VERSION ""

NS_ :

BS_:

BU_: Bms

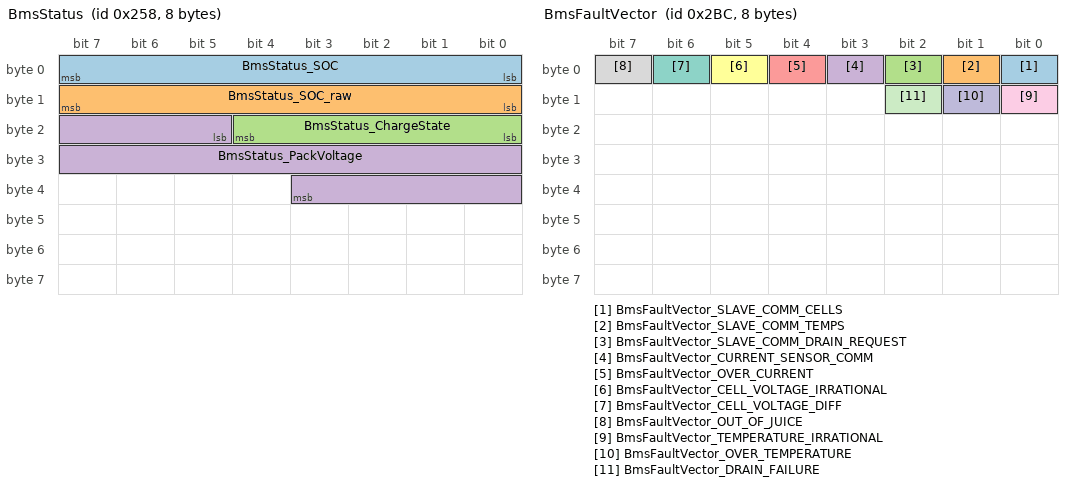
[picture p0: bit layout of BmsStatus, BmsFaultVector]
BO_ 600 BmsStatus: 8  Bms
 SG_ BmsStatus_SOC: 0|8@1+ (1,0) [0|100] "%" Vector__XXX
 SG_ BmsStatus_SOC_raw: 8|8@1+ (1,0) [0|100] "%" Vector__XXX
 SG_ BmsStatus_ChargeState: 16|5@1+ (1,0) [0|4] "" Vector__XXX
 SG_ BmsStatus_PackVoltage: 21|15@1+ (0.1,0) [0|400] "V" Vector__XXX

BO_ 700 BmsFaultVector: 8 Bms
 SG_ BmsFaultVector_SLAVE_COMM_CELLS : 0|1@1+ (1,0) [0|1] "" Vector__XXX
 SG_ BmsFaultVector_SLAVE_COMM_TEMPS : 1|1@1+ (1,0) [0|1] "" Vector__XXX
 SG_ BmsFaultVector_SLAVE_COMM_DRAIN_REQUEST : 2|1@1+ (1,0) [0|1] "" Vector__XXX
 SG_ BmsFaultVector_CURRENT_SENSOR_COMM : 3|1@1+ (1,0) [0|1] "" Vector__XXX
 SG_ BmsFaultVector_OVER_CURRENT : 4|1@1+ (1,0) [0|1] "" Vector__XXX
 SG_ BmsFaultVector_CELL_VOLTAGE_IRRATIONAL : 5|1@1+ (1,0) [0|1] "" Vector__XXX
 SG_ BmsFaultVector_CELL_VOLTAGE_DIFF : 6|1@1+ (1,0) [0|1] "" Vector__XXX
 SG_ BmsFaultVector_OUT_OF_JUICE : 7|1@1+ (1,0) [0|1] "" Vector__XXX
 SG_ BmsFaultVector_TEMPERATURE_IRRATIONAL: 8|1@1+ (1,0) [0|1] "" Vector__XXX
 SG_ BmsFaultVector_OVER_TEMPERATURE: 9|1@1+ (1,0) [0|1] "" Vector__XXX
 SG_ BmsFaultVector_DRAIN_FAILURE: 10|1@1+ (1,0) [0|1] "" Vector__XXX

BO_ 701 BmsFaultAlert: 8 Bms
 SG_ BmsFaultAlert_code M : 0|6@1+ (1,0) [0|63] "" Vector__XXX
 SG_ BmsFaultAlert_cell_comm_slave_board_num m0: 6|8@1+ (1,0) [0|255] "" Vector__XXX
 SG_ BmsFaultAlert_temp_comm_slave_board_num m1: 6|8@1+ (1,0) [0|255] "" Vector__XXX
 SG_ BmsFaultAlert_drain_comm_slave_board_num m2: 6|8@1+ (1,0) [0|255] "" Vector__XXX
 SG_ BmsFaultAlert_adc_error_code m3: 6|8@1+ (1,0) [0|255] "" Vector__XXX
 SG_ BmsFaultAlert_current m4: 6|32@1+ (0.001,0) [0|2000] "A" Vector__XXX
 SG_ BmsFaultAlert_irrational_voltage m5: 6|9@1+ (0.01,0) [0|5.12] "V" Vector__XXX
 SG_ BmsFaultAlert_voltage_diff m6: 6|9@1+ (0.01,0) [0|5.12] "V" Vector__XXX
 SG_ BmsFaultAlert_lowest_cell_voltage m7: 6|9@1+ (0.01,0) [0|5.12] "V" Vector__XXX
 SG_ BmsFaultAlert_irrational_temperature m8: 6|16@1+ (0.01,0) [-327.68|327.67] "V" Vector__XXX
 SG_ BmsFaultAlert_over_temperature m9: 6|16@1+ (0.01,0) [-327.68|327.67] "V" Vector__XXX
 SG_ BmsFaultAlert_failed_drain_cell m10: 6|8@1+ (1,0) [0|255] "" Vector__XXX

BO_ 702 BmsVoltages: 8 Bms
 SG_ BmsVoltages_mux M : 0|8@1+ (1,0) [0|255] "" Vector__XXX
 SG_ BmsVoltages_Cell0 m0 : 8|9@1+ (0.01,0) [0|5.12] "V" Vector__XXX
 SG_ BmsVoltages_Cell1 m0 : 17|9@1+ (0.01,0) [0|5.12] "V" Vector__XXX
 SG_ BmsVoltages_Cell2 m0 : 26|9@1+ (0.01,0) [0|5.12] "V" Vector__XXX
 SG_ BmsVoltages_Cell3 m0 : 35|9@1+ (0.01,0) [0|5.12] "V" Vector__XXX
 SG_ BmsVoltages_Cell4 m0 : 44|9@1+ (0.01,0) [0|5.12] "V" Vector__XXX
 SG_ BmsVoltages_Cell5 m0 : 53|9@1+ (0.01,0) [0|5.12] "V" Vector__XXX
 SG_ BmsVoltages_Cell6 m1 : 8|9@1+ (0.01,0) [0|5.12] "V" Vector__XXX
 SG_ BmsVoltages_Cell7 m1 : 17|9@1+ (0.01,0) [0|5.12] "V" Vector__XXX
 SG_ BmsVoltages_Cell8 m1 : 26|9@1+ (0.01,0) [0|5.12] "V" Vector__XXX
 SG_ BmsVoltages_Cell9 m1 : 35|9@1+ (0.01,0) [0|5.12] "V" Vector__XXX
 SG_ BmsVoltages_Cell10 m1 : 44|9@1+ (0.01,0) [0|5.12] "V" Vector__XXX
 SG_ BmsVoltages_Cell11 m1 : 53|9@1+ (0.01,0) [0|5.12] "V" Vector__XXX
 SG_ BmsVoltages_Cell12 m2 : 8|9@1+ (0.01,0) [0|5.12] "V" Vector__XXX
 SG_ BmsVoltages_Cell13 m2 : 17|9@1+ (0.01,0) [0|5.12] "V" Vector__XXX
 SG_ BmsVoltages_Cell14 m2 : 26|9@1+ (0.01,0) [0|5.12] "V" Vector__XXX
 SG_ BmsVoltages_Cell15 m2 : 35|9@1+ (0.01,0) [0|5.12] "V" Vector__XXX
 SG_ BmsVoltages_Cell16 m2 : 44|9@1+ (0.01,0) [0|5.12] "V" Vector__XXX
 SG_ BmsVoltages_Cell17 m2 : 53|9@1+ (0.01,0) [0|5.12] "V" Vector__XXX
 SG_ BmsVoltages_Cell18 m3 : 8|9@1+ (0.01,0) [0|5.12] "V" Vector__XXX
 SG_ BmsVoltages_Cell19 m3 : 17|9@1+ (0.01,0) [0|5.12] "V" Vector__XXX
 SG_ BmsVoltages_Cell20 m3 : 26|9@1+ (0.01,0) [0|5.12] "V" Vector__XXX
 SG_ BmsVoltages_Cell21 m3 : 35|9@1+ (0.01,0) [0|5.12] "V" Vector__XXX
 SG_ BmsVoltages_Cell22 m3 : 44|9@1+ (0.01,0) [0|5.12] "V" Vector__XXX
 SG_ BmsVoltages_Cell23 m3 : 53|9@1+ (0.01,0) [0|5.12] "V" Vector__XXX
 SG_ BmsVoltages_Cell24 m4 : 8|9@1+ (0.01,0) [0|5.12] "V" Vector__XXX
 SG_ BmsVoltages_Cell25 m4: 17|9@1+ (0.01,0) [0|5.12] "V" Vector__XXX
 SG_ BmsVoltages_Cell26 m4: 26|9@1+ (0.01,0) [0|5.12] "V" Vector__XXX
 SG_ BmsVoltages_Cell27 m4: 35|9@1+ (0.01,0) [0|5.12] "V" Vector__XXX
 SG_ BmsVoltages_Cell28 m4: 44|9@1+ (0.01,0) [0|5.12] "V" Vector__XXX
 SG_ BmsVoltages_Cell29 m4: 53|9@1+ (0.01,0) [0|5.12] "V" Vector__XXX
 SG_ BmsVoltages_Cell30 m5: 8|9@1+ (0.01,0) [0|5.12] "V" Vector__XXX
 SG_ BmsVoltages_Cell31 m5: 17|9@1+ (0.01,0) [0|5.12] "V" Vector__XXX
 SG_ BmsVoltages_Cell32 m5: 26|9@1+ (0.01,0) [0|5.12] "V" Vector__XXX
 SG_ BmsVoltages_Cell33 m5: 35|9@1+ (0.01,0) [0|5.12] "V" Vector__XXX
 SG_ BmsVoltages_Cell34 m5: 44|9@1+ (0.01,0) [0|5.12] "V" Vector__XXX
 SG_ BmsVoltages_Cell35 m5: 53|9@1+ (0.01,0) [0|5.12] "V" Vector__XXX
 SG_ BmsVoltages_Cell36 m6: 8|9@1+ (0.01,0) [0|5.12] "V" Vector__XXX
 SG_ BmsVoltages_Cell37 m6: 17|9@1+ (0.01,0) [0|5.12] "V" Vector__XXX
 SG_ BmsVoltages_Cell38 m6: 26|9@1+ (0.01,0) [0|5.12] "V" Vector__XXX
 SG_ BmsVoltages_Cell39 m6: 35|9@1+ (0.01,0) [0|5.12] "V" Vector__XXX
 SG_ BmsVoltages_Cell40 m6: 44|9@1+ (0.01,0) [0|5.12] "V" Vector__XXX
 SG_ BmsVoltages_Cell41 m6: 53|9@1+ (0.01,0) [0|5.12] "V" Vector__XXX
 SG_ BmsVoltages_Cell42 m7: 8|9@1+ (0.01,0) [0|5.12] "V" Vector__XXX
 SG_ BmsVoltages_Cell43 m7: 17|9@1+ (0.01,0) [0|5.12] "V" Vector__XXX
 SG_ BmsVoltages_Cell44 m7: 26|9@1+ (0.01,0) [0|5.12] "V" Vector__XXX
 SG_ BmsVoltages_Cell45 m7: 35|9@1+ (0.01,0) [0|5.12] "V" Vector__XXX
 SG_ BmsVoltages_Cell46 m7: 44|9@1+ (0.01,0) [0|5.12] "V" Vector__XXX
 SG_ BmsVoltages_Cell47 m7: 53|9@1+ (0.01,0) [0|5.12] "V" Vector__XXX
 SG_ BmsVoltages_Cell48 m8: 8|9@1+ (0.01,0) [0|5.12] "V" Vector__XXX
 SG_ BmsVoltages_Cell49 m8: 17|9@1+ (0.01,0) [0|5.12] "V" Vector__XXX
 SG_ BmsVoltages_Cell50 m8: 26|9@1+ (0.01,0) [0|5.12] "V" Vector__XXX
 SG_ BmsVoltages_Cell51 m8: 35|9@1+ (0.01,0) [0|5.12] "V" Vector__XXX
 SG_ BmsVoltages_Cell52 m8: 44|9@1+ (0.01,0) [0|5.12] "V" Vector__XXX
 SG_ BmsVoltages_Cell53 m8: 53|9@1+ (0.01,0) [0|5.12] "V" Vector__XXX
 SG_ BmsVoltages_Cell54 m9: 8|9@1+ (0.01,0) [0|5.12] "V" Vector__XXX
 SG_ BmsVoltages_Cell55 m9: 17|9@1+ (0.01,0) [0|5.12] "V" Vector__XXX
 SG_ BmsVoltages_Cell56 m9: 26|9@1+ (0.01,0) [0|5.12] "V" Vector__XXX
 SG_ BmsVoltages_Cell57 m9: 35|9@1+ (0.01,0) [0|5.12] "V" Vector__XXX
 SG_ BmsVoltages_Cell58 m9: 44|9@1+ (0.01,0) [0|5.12] "V" Vector__XXX
 SG_ BmsVoltages_Cell59 m9: 53|9@1+ (0.01,0) [0|5.12] "V" Vector__XXX
 SG_ BmsVoltages_Cell60 m10: 8|9@1+ (0.01,0) [0|5.12] "V" Vector__XXX
 SG_ BmsVoltages_Cell61 m10: 17|9@1+ (0.01,0) [0|5.12] "V" Vector__XXX
 SG_ BmsVoltages_Cell62 m10: 26|9@1+ (0.01,0) [0|5.12] "V" Vector__XXX
 SG_ BmsVoltages_Cell63 m10: 35|9@1+ (0.01,0) [0|5.12] "V" Vector__XXX
 SG_ BmsVoltages_Cell64 m10: 44|9@1+ (0.01,0) [0|5.12] "V" Vector__XXX
 SG_ BmsVoltages_Cell65 m10: 53|9@1+ (0.01,0) [0|5.12] "V" Vector__XXX
 SG_ BmsVoltages_Cell66 m11: 8|9@1+ (0.01,0) [0|5.12] "V" Vector__XXX
 SG_ BmsVoltages_Cell67 m11: 17|9@1+ (0.01,0) [0|5.12] "V" Vector__XXX
 SG_ BmsVoltages_Cell68 m11: 26|9@1+ (0.01,0) [0|5.12] "V" Vector__XXX
 SG_ BmsVoltages_Cell69 m11: 35|9@1+ (0.01,0) [0|5.12] "V" Vector__XXX
 SG_ BmsVoltages_Cell70 m11: 44|9@1+ (0.01,0) [0|5.12] "V" Vector__XXX
 SG_ BmsVoltages_Cell71 m11: 53|9@1+ (0.01,0) [0|5.12] "V" Vector__XXX
 SG_ BmsVoltages_Cell72 m12: 8|9@1+ (0.01,0) [0|5.12] "V" Vector__XXX
 SG_ BmsVoltages_Cell73 m12: 17|9@1+ (0.01,0) [0|5.12] "V" Vector__XXX
 SG_ BmsVoltages_Cell74 m12: 26|9@1+ (0.01,0) [0|5.12] "V" Vector__XXX
 SG_ BmsVoltages_Cell75 m12: 35|9@1+ (0.01,0) [0|5.12] "V" Vector__XXX
 SG_ BmsVoltages_Cell76 m12: 44|9@1+ (0.01,0) [0|5.12] "V" Vector__XXX
 SG_ BmsVoltages_Cell77 m12: 53|9@1+ (0.01,0) [0|5.12] "V" Vector__XXX
 SG_ BmsVoltages_Cell78 m13: 8|9@1+ (0.01,0) [0|5.12] "V" Vector__XXX
 SG_ BmsVoltages_Cell79 m13: 17|9@1+ (0.01,0) [0|5.12] "V" Vector__XXX
 SG_ BmsVoltages_Cell80 m13: 26|9@1+ (0.01,0) [0|5.12] "V" Vector__XXX
 SG_ BmsVoltages_Cell81 m13: 35|9@1+ (0.01,0) [0|5.12] "V" Vector__XXX
 SG_ BmsVoltages_Cell82 m13: 44|9@1+ (0.01,0) [0|5.12] "V" Vector__XXX
 SG_ BmsVoltages_Cell83 m13: 53|9@1+ (0.01,0) [0|5.12] "V" Vector__XXX
 SG_ BmsVoltages_Cell84 m14: 8|9@1+ (0.01,0) [0|5.12] "V" Vector__XXX
 SG_ BmsVoltages_Cell85 m14: 17|9@1+ (0.01,0) [0|5.12] "V" Vector__XXX
 SG_ BmsVoltages_Cell86 m14: 26|9@1+ (0.01,0) [0|5.12] "V" Vector__XXX
 SG_ BmsVoltages_Cell87 m14: 35|9@1+ (0.01,0) [0|5.12] "V" Vector__XXX
 SG_ BmsVoltages_Cell88 m14: 44|9@1+ (0.01,0) [0|5.12] "V" Vector__XXX
 SG_ BmsVoltages_Cell89 m14: 53|9@1+ (0.01,0) [0|5.12] "V" Vector__XXX

BO_ 703 BmsThermistorVoltages: 8 Bms
 SG_ BmsThermistorVoltages_mux M : 0|2@1+ (1,0) [0|3] "" Vector__XXX
 SG_ BmsThermistorVoltages_tm0 m0: 2|9@1+ (0.01,0) [0|5.12] "V" Vector__XXX
 SG_ BmsThermistorVoltages_tm1 m0: 11|9@1+ (0.01,0) [0|5.12] "V" Vector__XXX
 SG_ BmsThermistorVoltages_tm2 m0: 20|9@1+ (0.01,0) [0|5.12] "V" Vector__XXX
 SG_ BmsThermistorVoltages_tm3 m0: 29|9@1+ (0.01,0) [0|5.12] "V" Vector__XXX
 SG_ BmsThermistorVoltages_tm4 m0: 38|9@1+ (0.01,0) [0|5.12] "V" Vector__XXX
 SG_ BmsThermistorVoltages_tm5 m0: 47|9@1+ (0.01,0) [0|5.12] "V" Vector__XXX
 SG_ BmsThermistorVoltages_tm6 m1: 2|9@1+ (0.01,0) [0|5.12] "V" Vector__XXX
 SG_ BmsThermistorVoltages_tm7 m1: 11|9@1+ (0.01,0) [0|5.12] "V" Vector__XXX
 SG_ BmsThermistorVoltages_tm8 m1: 20|9@1+ (0.01,0) [0|5.12] "V" Vector__XXX
 SG_ BmsThermistorVoltages_tm9 m1: 29|9@1+ (0.01,0) [0|5.12] "V" Vector__XXX
 SG_ BmsThermistorVoltages_tm10 m1: 38|9@1+ (0.01,0) [0|5.12] "V" Vector__XXX
 SG_ BmsThermistorVoltages_tm11 m1: 47|9@1+ (0.01,0) [0|5.12] "V" Vector__XXX
 SG_ BmsThermistorVoltages_tm12 m2: 2|9@1+ (0.01,0) [0|5.12] "V" Vector__XXX
 SG_ BmsThermistorVoltages_tm13 m2: 11|9@1+ (0.01,0) [0|5.12] "V" Vector__XXX
 SG_ BmsThermistorVoltages_tm14 m2: 20|9@1+ (0.01,0) [0|5.12] "V" Vector__XXX
 SG_ BmsThermistorVoltages_tm15 m2: 29|9@1+ (0.01,0) [0|5.12] "V" Vector__XXX
 SG_ BmsThermistorVoltages_tm16 m2: 38|9@1+ (0.01,0) [0|5.12] "V" Vector__XXX
 SG_ BmsThermistorVoltages_tm17 m2: 47|9@1+ (0.01,0) [0|5.12] "V" Vector__XXX
 SG_ BmsThermistorVoltages_tm18 m3: 2|9@1+ (0.01,0) [0|5.12] "V" Vector__XXX
 SG_ BmsThermistorVoltages_tm19 m3: 11|9@1+ (0.01,0) [0|5.12] "V" Vector__XXX

BO_ 704 BmsTemperatures: 8 Bms
 SG_ BmsTemperatures_mux M : 0|2@1+ (1,0) [0|3] "" Vector__XXX
 SG_ BmsTemperatures_0 m0: 2|8@1- (1,0) [-128|127] "C" Vector__XXX
 SG_ BmsTemperatures_1 m0: 10|8@1- (1,0) [-128|127] "C" Vector__XXX
 SG_ BmsTemperatures_2 m0: 18|8@1- (1,0) [-128|127] "C" Vector__XXX
 SG_ BmsTemperatures_3 m0: 26|8@1- (1,0) [-128|127] "C" Vector__XXX
 SG_ BmsTemperatures_4 m0: 34|8@1- (1,0) [-128|127] "C" Vector__XXX
 SG_ BmsTemperatures_5 m0: 42|8@1- (1,0) [-128|127] "C" Vector__XXX
 SG_ BmsTemperatures_6 m0: 50|8@1- (1,0) [-128|127] "C" Vector__XXX
 SG_ BmsTemperatures_7 m1: 2|8@1- (1,0) [-128|127] "C" Vector__XXX
 SG_ BmsTemperatures_8 m1: 10|8@1- (1,0) [-128|127] "C" Vector__XXX
 SG_ BmsTemperatures_9 m1: 18|8@1- (1,0) [-128|127] "C" Vector__XXX
 SG_ BmsTemperatures_10 m1: 26|8@1- (1,0) [-128|127] "C" Vector__XXX
 SG_ BmsTemperatures_11 m1: 34|8@1- (1,0) [-128|127] "C" Vector__XXX
 SG_ BmsTemperatures_12 m1: 42|8@1- (1,0) [-128|127] "C" Vector__XXX
 SG_ BmsTemperatures_13 m1: 50|8@1- (1,0) [-128|127] "C" Vector__XXX
 SG_ BmsTemperatures_14 m2: 2|8@1- (1,0) [-128|127] "C" Vector__XXX
 SG_ BmsTemperatures_15 m2: 10|8@1- (1,0) [-128|127] "C" Vector__XXX
 SG_ BmsTemperatures_16 m2: 18|8@1- (1,0) [-128|127] "C" Vector__XXX
 SG_ BmsTemperatures_17 m2: 26|8@1- (1,0) [-128|127] "C" Vector__XXX
 SG_ BmsTemperatures_18 m2: 34|8@1- (1,0) [-128|127] "C" Vector__XXX
 SG_ BmsTemperatures_19 m2: 42|8@1- (1,0) [-128|127] "C" Vector__XXX

BO_ 800 BmsDrainStatusA: 8 Bms
 SG_ BmsDrainStatusA_Cell0: 0|1@1+ (1,0) [0|1] "" Vector__XXX
 SG_ BmsDrainStatusA_Cell1: 1|1@1+ (1,0) [0|1] "" Vector__XXX
 SG_ BmsDrainStatusA_Cell2: 2|1@1+ (1,0) [0|1] "" Vector__XXX
 SG_ BmsDrainStatusA_Cell3: 3|1@1+ (1,0) [0|1] "" Vector__XXX
 SG_ BmsDrainStatusA_Cell4: 4|1@1+ (1,0) [0|1] "" Vector__XXX
 SG_ BmsDrainStatusA_Cell5: 5|1@1+ (1,0) [0|1] "" Vector__XXX
 SG_ BmsDrainStatusA_Cell6: 6|1@1+ (1,0) [0|1] "" Vector__XXX
 SG_ BmsDrainStatusA_Cell7: 7|1@1+ (1,0) [0|1] "" Vector__XXX
 SG_ BmsDrainStatusA_Cell8: 8|1@1+ (1,0) [0|1] "" Vector__XXX
 SG_ BmsDrainStatusA_Cell9: 9|1@1+ (1,0) [0|1] "" Vector__XXX
 SG_ BmsDrainStatusA_Cell10: 10|1@1+ (1,0) [0|1] "" Vector__XXX
 SG_ BmsDrainStatusA_Cell11: 11|1@1+ (1,0) [0|1] "" Vector__XXX
 SG_ BmsDrainStatusA_Cell12: 12|1@1+ (1,0) [0|1] "" Vector__XXX
 SG_ BmsDrainStatusA_Cell13: 13|1@1+ (1,0) [0|1] "" Vector__XXX
 SG_ BmsDrainStatusA_Cell14: 14|1@1+ (1,0) [0|1] "" Vector__XXX
 SG_ BmsDrainStatusA_Cell15: 15|1@1+ (1,0) [0|1] "" Vector__XXX
 SG_ BmsDrainStatusA_Cell16: 16|1@1+ (1,0) [0|1] "" Vector__XXX
 SG_ BmsDrainStatusA_Cell17: 17|1@1+ (1,0) [0|1] "" Vector__XXX
 SG_ BmsDrainStatusA_Cell18: 18|1@1+ (1,0) [0|1] "" Vector__XXX
 SG_ BmsDrainStatusA_Cell19: 19|1@1+ (1,0) [0|1] "" Vector__XXX
 SG_ BmsDrainStatusA_Cell20: 20|1@1+ (1,0) [0|1] "" Vector__XXX
 SG_ BmsDrainStatusA_Cell21: 21|1@1+ (1,0) [0|1] "" Vector__XXX
 SG_ BmsDrainStatusA_Cell22: 22|1@1+ (1,0) [0|1] "" Vector__XXX
 SG_ BmsDrainStatusA_Cell23: 23|1@1+ (1,0) [0|1] "" Vector__XXX
 SG_ BmsDrainStatusA_Cell24: 24|1@1+ (1,0) [0|1] "" Vector__XXX
 SG_ BmsDrainStatusA_Cell25: 25|1@1+ (1,0) [0|1] "" Vector__XXX
 SG_ BmsDrainStatusA_Cell26: 26|1@1+ (1,0) [0|1] "" Vector__XXX
 SG_ BmsDrainStatusA_Cell27: 27|1@1+ (1,0) [0|1] "" Vector__XXX
 SG_ BmsDrainStatusA_Cell28: 28|1@1+ (1,0) [0|1] "" Vector__XXX
 SG_ BmsDrainStatusA_Cell29: 29|1@1+ (1,0) [0|1] "" Vector__XXX
 SG_ BmsDrainStatusA_Cell30: 30|1@1+ (1,0) [0|1] "" Vector__XXX
 SG_ BmsDrainStatusA_Cell31: 31|1@1+ (1,0) [0|1] "" Vector__XXX
 SG_ BmsDrainStatusA_Cell32: 32|1@1+ (1,0) [0|1] "" Vector__XXX
 SG_ BmsDrainStatusA_Cell33: 33|1@1+ (1,0) [0|1] "" Vector__XXX
 SG_ BmsDrainStatusA_Cell34: 34|1@1+ (1,0) [0|1] "" Vector__XXX
 SG_ BmsDrainStatusA_Cell35: 35|1@1+ (1,0) [0|1] "" Vector__XXX
 SG_ BmsDrainStatusA_Cell36: 36|1@1+ (1,0) [0|1] "" Vector__XXX
 SG_ BmsDrainStatusA_Cell37: 37|1@1+ (1,0) [0|1] "" Vector__XXX
 SG_ BmsDrainStatusA_Cell38: 38|1@1+ (1,0) [0|1] "" Vector__XXX
 SG_ BmsDrainStatusA_Cell39: 39|1@1+ (1,0) [0|1] "" Vector__XXX
 SG_ BmsDrainStatusA_Cell40: 40|1@1+ (1,0) [0|1] "" Vector__XXX
 SG_ BmsDrainStatusA_Cell41: 41|1@1+ (1,0) [0|1] "" Vector__XXX
 SG_ BmsDrainStatusA_Cell42: 42|1@1+ (1,0) [0|1] "" Vector__XXX
 SG_ BmsDrainStatusA_Cell43: 43|1@1+ (1,0) [0|1] "" Vector__XXX
 SG_ BmsDrainStatusA_Cell44: 44|1@1+ (1,0) [0|1] "" Vector__XXX
 SG_ BmsDrainStatusA_Cell45: 45|1@1+ (1,0) [0|1] "" Vector__XXX
 SG_ BmsDrainStatusA_Cell46: 46|1@1+ (1,0) [0|1] "" Vector__XXX
 SG_ BmsDrainStatusA_Cell47: 47|1@1+ (1,0) [0|1] "" Vector__XXX
 SG_ BmsDrainStatusA_Cell48: 48|1@1+ (1,0) [0|1] "" Vector__XXX
 SG_ BmsDrainStatusA_Cell49: 49|1@1+ (1,0) [0|1] "" Vector__XXX
 SG_ BmsDrainStatusA_Cell50: 50|1@1+ (1,0) [0|1] "" Vector__XXX
 SG_ BmsDrainStatusA_Cell51: 51|1@1+ (1,0) [0|1] "" Vector__XXX
 SG_ BmsDrainStatusA_Cell52: 52|1@1+ (1,0) [0|1] "" Vector__XXX
 SG_ BmsDrainStatusA_Cell53: 53|1@1+ (1,0) [0|1] "" Vector__XXX
 SG_ BmsDrainStatusA_Cell54: 54|1@1+ (1,0) [0|1] "" Vector__XXX
 SG_ BmsDrainStatusA_Cell55: 55|1@1+ (1,0) [0|1] "" Vector__XXX
 SG_ BmsDrainStatusA_Cell56: 56|1@1+ (1,0) [0|1] "" Vector__XXX
 SG_ BmsDrainStatusA_Cell57: 57|1@1+ (1,0) [0|1] "" Vector__XXX
 SG_ BmsDrainStatusA_Cell58: 58|1@1+ (1,0) [0|1] "" Vector__XXX
 SG_ BmsDrainStatusA_Cell59: 59|1@1+ (1,0) [0|1] "" Vector__XXX
 SG_ BmsDrainStatusA_Cell60: 60|1@1+ (1,0) [0|1] "" Vector__XXX
 SG_ BmsDrainStatusA_Cell61: 61|1@1+ (1,0) [0|1] "" Vector__XXX
 SG_ BmsDrainStatusA_Cell62: 62|1@1+ (1,0) [0|1] "" Vector__XXX
 SG_ BmsDrainStatusA_Cell63: 63|1@1+ (1,0) [0|1] "" Vector__XXX

BO_ 801 BmsDrainStatusB: 8 Bms
 SG_ BmsDrainStatusB_Cell64: 0|1@1+ (1,0) [0|1] "" Vector__XXX
 SG_ BmsDrainStatusB_Cell65: 1|1@1+ (1,0) [0|1] "" Vector__XXX
 SG_ BmsDrainStatusB_Cell66: 2|1@1+ (1,0) [0|1] "" Vector__XXX
 SG_ BmsDrainStatusB_Cell67: 3|1@1+ (1,0) [0|1] "" Vector__XXX
 SG_ BmsDrainStatusB_Cell68: 4|1@1+ (1,0) [0|1] "" Vector__XXX
 SG_ BmsDrainStatusB_Cell69: 5|1@1+ (1,0) [0|1] "" Vector__XXX
 SG_ BmsDrainStatusB_Cell70: 6|1@1+ (1,0) [0|1] "" Vector__XXX
 SG_ BmsDrainStatusB_Cell71: 7|1@1+ (1,0) [0|1] "" Vector__XXX
 SG_ BmsDrainStatusB_Cell72: 8|1@1+ (1,0) [0|1] "" Vector__XXX
 SG_ BmsDrainStatusB_Cell73: 9|1@1+ (1,0) [0|1] "" Vector__XXX
 SG_ BmsDrainStatusB_Cell74: 10|1@1+ (1,0) [0|1] "" Vector__XXX
 SG_ BmsDrainStatusB_Cell75: 11|1@1+ (1,0) [0|1] "" Vector__XXX
 SG_ BmsDrainStatusB_Cell76: 12|1@1+ (1,0) [0|1] "" Vector__XXX
 SG_ BmsDrainStatusB_Cell77: 13|1@1+ (1,0) [0|1] "" Vector__XXX
 SG_ BmsDrainStatusB_Cell78: 14|1@1+ (1,0) [0|1] "" Vector__XXX
 SG_ BmsDrainStatusB_Cell79: 15|1@1+ (1,0) [0|1] "" Vector__XXX
 SG_ BmsDrainStatusB_Cell80: 16|1@1+ (1,0) [0|1] "" Vector__XXX
 SG_ BmsDrainStatusB_Cell81: 17|1@1+ (1,0) [0|1] "" Vector__XXX
 SG_ BmsDrainStatusB_Cell82: 18|1@1+ (1,0) [0|1] "" Vector__XXX
 SG_ BmsDrainStatusB_Cell83: 19|1@1+ (1,0) [0|1] "" Vector__XXX
 SG_ BmsDrainStatusB_Cell84: 20|1@1+ (1,0) [0|1] "" Vector__XXX
 SG_ BmsDrainStatusB_Cell85: 21|1@1+ (1,0) [0|1] "" Vector__XXX
 SG_ BmsDrainStatusB_Cell86: 22|1@1+ (1,0) [0|1] "" Vector__XXX
 SG_ BmsDrainStatusB_Cell87: 23|1@1+ (1,0) [0|1] "" Vector__XXX
 SG_ BmsDrainStatusB_Cell88: 24|1@1+ (1,0) [0|1] "" Vector__XXX
 SG_ BmsDrainStatusB_Cell89: 25|1@1+ (1,0) [0|1] "" Vector__XXX

BO_ 900 BmsCurrent: 8 Bms
 SG_ BmsInstCurrentFilt : 0|32@1- (0.001,0) [-100|250] "A" Vector__XXX

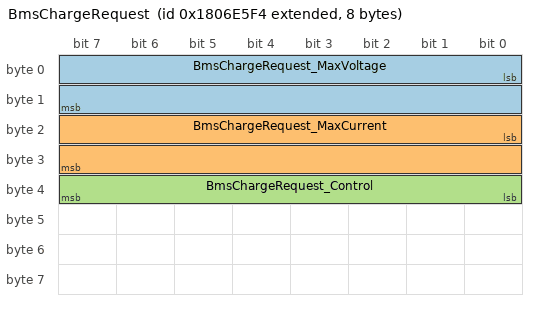
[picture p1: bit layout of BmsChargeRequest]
BO_ 2550588916 BmsChargeRequest: 8 Bms
 SG_ BmsChargeRequest_MaxVoltage: 0|16@1+ (0.1,0) [0|6553.3] "V" Vector__XXX
 SG_ BmsChargeRequest_MaxCurrent: 16|16@1+ (0.1,0) [0|6553.3] "A" Vector__XXX
 SG_ BmsChargeRequest_Control: 32|8@1+ (1,0) [0|1] "" Vector__XXX

BO_ 950 BmsHardFaultIndicator: 8 Bms
 SG_ BmsHardFaultIndicator_task: 0|4@1+ (1,0) [0|15] "" Vector__XXX

BO_ 951 BmsRef: 8 Bms
 SG_ BmsRef_mux M: 0|1@1+ (1,0) [0|1] "" Vector__XXX
 SG_ BmsRef_ref0 m0: 1|9@1+ (0.01,0) [0|5.12] "V" Vector__XXX
 SG_ BmsRef_ref1 m0: 10|9@1+ (0.01,0) [0|5.12] "V" Vector__XXX
 SG_ BmsRef_ref2 m0: 19|9@1+ (0.01,0) [0|5.12] "V" Vector__XXX
 SG_ BmsRef_ref3 m0: 28|9@1+ (0.01,0) [0|5.12] "V" Vector__XXX
 SG_ BmsRef_ref4 m0: 37|9@1+ (0.01,0) [0|5.12] "V" Vector__XXX
 SG_ BmsRef_ref5 m0: 46|9@1+ (0.01,0) [0|5.12] "V" Vector__XXX
 SG_ BmsRef_ref6 m1: 1|9@1+ (0.01,0) [0|5.12] "V" Vector__XXX
 SG_ BmsRef_ref7 m1: 10|9@1+ (0.01,0) [0|5.12] "V" Vector__XXX
 SG_ BmsRef_ref8 m1: 19|9@1+ (0.01,0) [0|5.12] "V" Vector__XXX
 SG_ BmsRef_ref9 m1: 28|9@1+ (0.01,0) [0|5.12] "V" Vector__XXX
 SG_ BmsRef_ref10 m1: 37|9@1+ (0.01,0) [0|5.12] "V" Vector__XXX
 SG_ BmsRef_ref11 m1: 46|9@1+ (0.01,0) [0|5.12] "V" Vector__XXX

BO_ 702 BmsInternalResistances: 8 Bms
 SG_ BmsResistance_mux M : 0|8@1+ (1,0) [0|255] "" Vector__XXX
 SG_ BmsResistance_Cell0 m0 : 8|9@1+ (0.01,0) [0|5.12] "V" Vector__XXX
 SG_ BmsResistance_Cell1 m0 : 17|9@1+ (0.01,0) [0|5.12] "V" Vector__XXX
 SG_ BmsResistance_Cell2 m0 : 26|9@1+ (0.01,0) [0|5.12] "V" Vector__XXX
 SG_ BmsResistance_Cell3 m0 : 35|9@1+ (0.01,0) [0|5.12] "V" Vector__XXX
 SG_ BmsResistance_Cell4 m0 : 44|9@1+ (0.01,0) [0|5.12] "V" Vector__XXX
 SG_ BmsResistance_Cell5 m0 : 53|9@1+ (0.01,0) [0|5.12] "V" Vector__XXX
 SG_ BmsResistance_Cell6 m1 : 8|9@1+ (0.01,0) [0|5.12] "V" Vector__XXX
 SG_ BmsResistance_Cell7 m1 : 17|9@1+ (0.01,0) [0|5.12] "V" Vector__XXX
 SG_ BmsResistance_Cell8 m1 : 26|9@1+ (0.01,0) [0|5.12] "V" Vector__XXX
 SG_ BmsResistance_Cell9 m1 : 35|9@1+ (0.01,0) [0|5.12] "V" Vector__XXX
 SG_ BmsResistance_Cell10 m1 : 44|9@1+ (0.01,0) [0|5.12] "V" Vector__XXX
 SG_ BmsResistance_Cell11 m1 : 53|9@1+ (0.01,0) [0|5.12] "V" Vector__XXX
 SG_ BmsResistance_Cell12 m2 : 8|9@1+ (0.01,0) [0|5.12] "V" Vector__XXX
 SG_ BmsResistance_Cell13 m2 : 17|9@1+ (0.01,0) [0|5.12] "V" Vector__XXX
 SG_ BmsResistance_Cell14 m2 : 26|9@1+ (0.01,0) [0|5.12] "V" Vector__XXX
 SG_ BmsResistance_Cell15 m2 : 35|9@1+ (0.01,0) [0|5.12] "V" Vector__XXX
 SG_ BmsResistance_Cell16 m2 : 44|9@1+ (0.01,0) [0|5.12] "V" Vector__XXX
 SG_ BmsResistance_Cell17 m2 : 53|9@1+ (0.01,0) [0|5.12] "V" Vector__XXX
 SG_ BmsResistance_Cell18 m3 : 8|9@1+ (0.01,0) [0|5.12] "V" Vector__XXX
 SG_ BmsResistance_Cell19 m3 : 17|9@1+ (0.01,0) [0|5.12] "V" Vector__XXX
 SG_ BmsResistance_Cell20 m3 : 26|9@1+ (0.01,0) [0|5.12] "V" Vector__XXX
 SG_ BmsResistance_Cell21 m3 : 35|9@1+ (0.01,0) [0|5.12] "V" Vector__XXX
 SG_ BmsResistance_Cell22 m3 : 44|9@1+ (0.01,0) [0|5.12] "V" Vector__XXX
 SG_ BmsResistance_Cell23 m3 : 53|9@1+ (0.01,0) [0|5.12] "V" Vector__XXX
 SG_ BmsResistance_Cell24 m4 : 8|9@1+ (0.01,0) [0|5.12] "V" Vector__XXX
 SG_ BmsResistance_Cell25 m4: 17|9@1+ (0.01,0) [0|5.12] "V" Vector__XXX
 SG_ BmsResistance_Cell26 m4: 26|9@1+ (0.01,0) [0|5.12] "V" Vector__XXX
 SG_ BmsResistance_Cell27 m4: 35|9@1+ (0.01,0) [0|5.12] "V" Vector__XXX
 SG_ BmsResistance_Cell28 m4: 44|9@1+ (0.01,0) [0|5.12] "V" Vector__XXX
 SG_ BmsResistance_Cell29 m4: 53|9@1+ (0.01,0) [0|5.12] "V" Vector__XXX
 SG_ BmsResistance_Cell30 m5: 8|9@1+ (0.01,0) [0|5.12] "V" Vector__XXX
 SG_ BmsResistance_Cell31 m5: 17|9@1+ (0.01,0) [0|5.12] "V" Vector__XXX
 SG_ BmsResistance_Cell32 m5: 26|9@1+ (0.01,0) [0|5.12] "V" Vector__XXX
 SG_ BmsResistance_Cell33 m5: 35|9@1+ (0.01,0) [0|5.12] "V" Vector__XXX
 SG_ BmsResistance_Cell34 m5: 44|9@1+ (0.01,0) [0|5.12] "V" Vector__XXX
 SG_ BmsResistance_Cell35 m5: 53|9@1+ (0.01,0) [0|5.12] "V" Vector__XXX
 SG_ BmsResistance_Cell36 m6: 8|9@1+ (0.01,0) [0|5.12] "V" Vector__XXX
 SG_ BmsResistance_Cell37 m6: 17|9@1+ (0.01,0) [0|5.12] "V" Vector__XXX
 SG_ BmsResistance_Cell38 m6: 26|9@1+ (0.01,0) [0|5.12] "V" Vector__XXX
 SG_ BmsResistance_Cell39 m6: 35|9@1+ (0.01,0) [0|5.12] "V" Vector__XXX
 SG_ BmsResistance_Cell40 m6: 44|9@1+ (0.01,0) [0|5.12] "V" Vector__XXX
 SG_ BmsResistance_Cell41 m6: 53|9@1+ (0.01,0) [0|5.12] "V" Vector__XXX
 SG_ BmsResistance_Cell42 m7: 8|9@1+ (0.01,0) [0|5.12] "V" Vector__XXX
 SG_ BmsResistance_Cell43 m7: 17|9@1+ (0.01,0) [0|5.12] "V" Vector__XXX
 SG_ BmsResistance_Cell44 m7: 26|9@1+ (0.01,0) [0|5.12] "V" Vector__XXX
 SG_ BmsResistance_Cell45 m7: 35|9@1+ (0.01,0) [0|5.12] "V" Vector__XXX
 SG_ BmsResistance_Cell46 m7: 44|9@1+ (0.01,0) [0|5.12] "V" Vector__XXX
 SG_ BmsResistance_Cell47 m7: 53|9@1+ (0.01,0) [0|5.12] "V" Vector__XXX
 SG_ BmsResistance_Cell48 m8: 8|9@1+ (0.01,0) [0|5.12] "V" Vector__XXX
 SG_ BmsResistance_Cell49 m8: 17|9@1+ (0.01,0) [0|5.12] "V" Vector__XXX
 SG_ BmsResistance_Cell50 m8: 26|9@1+ (0.01,0) [0|5.12] "V" Vector__XXX
 SG_ BmsResistance_Cell51 m8: 35|9@1+ (0.01,0) [0|5.12] "V" Vector__XXX
 SG_ BmsResistance_Cell52 m8: 44|9@1+ (0.01,0) [0|5.12] "V" Vector__XXX
 SG_ BmsResistance_Cell53 m8: 53|9@1+ (0.01,0) [0|5.12] "V" Vector__XXX
 SG_ BmsResistance_Cell54 m9: 8|9@1+ (0.01,0) [0|5.12] "V" Vector__XXX
 SG_ BmsResistance_Cell55 m9: 17|9@1+ (0.01,0) [0|5.12] "V" Vector__XXX
 SG_ BmsResistance_Cell56 m9: 26|9@1+ (0.01,0) [0|5.12] "V" Vector__XXX
 SG_ BmsResistance_Cell57 m9: 35|9@1+ (0.01,0) [0|5.12] "V" Vector__XXX
 SG_ BmsResistance_Cell58 m9: 44|9@1+ (0.01,0) [0|5.12] "V" Vector__XXX
 SG_ BmsResistance_Cell59 m9: 53|9@1+ (0.01,0) [0|5.12] "V" Vector__XXX
 SG_ BmsResistance_Cell60 m10: 8|9@1+ (0.01,0) [0|5.12] "V" Vector__XXX
 SG_ BmsResistance_Cell61 m10: 17|9@1+ (0.01,0) [0|5.12] "V" Vector__XXX
 SG_ BmsResistance_Cell62 m10: 26|9@1+ (0.01,0) [0|5.12] "V" Vector__XXX
 SG_ BmsResistance_Cell63 m10: 35|9@1+ (0.01,0) [0|5.12] "V" Vector__XXX
 SG_ BmsResistance_Cell64 m10: 44|9@1+ (0.01,0) [0|5.12] "V" Vector__XXX
 SG_ BmsResistance_Cell65 m10: 53|9@1+ (0.01,0) [0|5.12] "V" Vector__XXX
 SG_ BmsResistance_Cell66 m11: 8|9@1+ (0.01,0) [0|5.12] "V" Vector__XXX
 SG_ BmsResistance_Cell67 m11: 17|9@1+ (0.01,0) [0|5.12] "V" Vector__XXX
 SG_ BmsResistance_Cell68 m11: 26|9@1+ (0.01,0) [0|5.12] "V" Vector__XXX
 SG_ BmsResistance_Cell69 m11: 35|9@1+ (0.01,0) [0|5.12] "V" Vector__XXX
 SG_ BmsResistance_Cell70 m11: 44|9@1+ (0.01,0) [0|5.12] "V" Vector__XXX
 SG_ BmsResistance_Cell71 m11: 53|9@1+ (0.01,0) [0|5.12] "V" Vector__XXX
 SG_ BmsResistance_Cell72 m12: 8|9@1+ (0.01,0) [0|5.12] "V" Vector__XXX
 SG_ BmsResistance_Cell73 m12: 17|9@1+ (0.01,0) [0|5.12] "V" Vector__XXX
 SG_ BmsResistance_Cell74 m12: 26|9@1+ (0.01,0) [0|5.12] "V" Vector__XXX
 SG_ BmsResistance_Cell75 m12: 35|9@1+ (0.01,0) [0|5.12] "V" Vector__XXX
 SG_ BmsResistance_Cell76 m12: 44|9@1+ (0.01,0) [0|5.12] "V" Vector__XXX
 SG_ BmsResistance_Cell77 m12: 53|9@1+ (0.01,0) [0|5.12] "V" Vector__XXX
 SG_ BmsResistance_Cell78 m13: 8|9@1+ (0.01,0) [0|5.12] "V" Vector__XXX
 SG_ BmsResistance_Cell79 m13: 17|9@1+ (0.01,0) [0|5.12] "V" Vector__XXX
 SG_ BmsResistance_Cell80 m13: 26|9@1+ (0.01,0) [0|5.12] "V" Vector__XXX
 SG_ BmsResistance_Cell81 m13: 35|9@1+ (0.01,0) [0|5.12] "V" Vector__XXX
 SG_ BmsResistance_Cell82 m13: 44|9@1+ (0.01,0) [0|5.12] "V" Vector__XXX
 SG_ BmsResistance_Cell83 m13: 53|9@1+ (0.01,0) [0|5.12] "V" Vector__XXX
 SG_ BmsResistance_Cell84 m14: 8|9@1+ (0.01,0) [0|5.12] "V" Vector__XXX
 SG_ BmsResistance_Cell85 m14: 17|9@1+ (0.01,0) [0|5.12] "V" Vector__XXX
 SG_ BmsResistance_Cell86 m14: 26|9@1+ (0.01,0) [0|5.12] "V" Vector__XXX
 SG_ BmsResistance_Cell87 m14: 35|9@1+ (0.01,0) [0|5.12] "V" Vector__XXX
 SG_ BmsResistance_Cell88 m14: 44|9@1+ (0.01,0) [0|5.12] "V" Vector__XXX
 SG_ BmsResistance_Cell89 m14: 53|9@1+ (0.01,0) [0|5.12] "V" Vector__XXX

VAL_ 701 BmsFaultAlert_code 0 "FaultCode_SLAVE_COMM_CELLS" 1 "FaultCode_SLAVE_COMM_TEMPS" 2 "FaultCode_SLAVE_COMM_DRAIN_REQUEST" 3 "FaultCode_CURRENT_SENSOR_COMM" 4 "FaultCode_OVER_CURRENT" 5 "FaultCode_CELL_VOLTAGE_IRRATIONAL" 6 "FaultCode_CELL_VOLTAGE_DIFF" 7 "Faultcode_OUT_OF_JUICE" 8 "FaultCode_TEMPERATURE_IRRATIONAL" 9 "FaultCode_OVER_TEMP" 10 "FaultCode_DRAIN_FAILURE";
VAL_ 600 BmsStatus_ChargeState 0 "ChargeState_DISCONNECTED" 1 "ChargeState_CONNECTED_COMPLETE" 2 "ChargeState_CONNECTED_BALANCING" 3 "ChargeState_CONNECTED_CHARGING" 4 "ChargeState_CONNECTED_BALANCE_SENSING";
VAL_ 950 BmsHardFaultIndicator_task 0 "unknown" 1 "task_1Hz" 2 "task_10Hz" 3 "task_1kHz" 4 "can_rx_task";
